# DCT_L3Interconnect register map
Vendor: Texas Instruments
Peripheral module from a debugger description file (folder omap4430).
Registers are 32-bit, access per field, reset 0x0 unless marked. A register's access mark holds for its fields unless they carry their own. Offsets are as the file gives them; lines under a group give offsets from that group; [hi:lo] are bit positions; {n}, {i} and the like mark numbered series; 'fields as' and 'values as' point back to an identical list; <NAME> marks a mode.

## DCT_L3Interconnect
0x00 DCT_VERSION ro reset not defined — IP Revision
  [31:0] REVISION
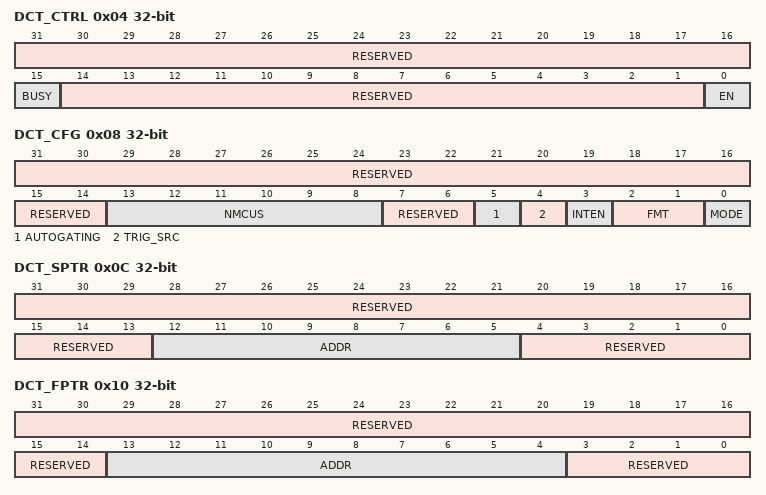
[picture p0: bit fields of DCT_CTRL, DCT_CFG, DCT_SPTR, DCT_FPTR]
0x04 DCT_CTRL — DCT control register
  [31:16] RESERVED ro — Read returns 0.
  [15] BUSY ro — IDCT/busy status 0: Idle 1: Busy
  [14:1] RESERVED ro — Read returns 0.
  [0] EN wo — Write 1 whenDCT_CFG[4] TRIG_SRC = 0 to start module operation. Read returns 0.
0x08 DCT_CFG — DCT configuration register
  [31:14] RESERVED ro — Read returns 0.
  [13:8] NMCUS rw — Number of MCUs (for FMT = 0, 1) or blocks (for FMT = 2) 0 = 1 MCU or block 1 = 2 MCUs or blocks ... 63 = 64 MCUs or blocks
  [7:6] RESERVED ro — Read returns 0.
  [5] AUTOGATING rw — Internal clock gating on interface and functional clocks 0: Clocks are free-running 1: Clocks are gated off in subblocks that are not required for operation.
  [4] TRIG_SRC rw — Trigger source 0: Memory mapper register 1: Hardware start signal
  [3] INTEN rw — 0: Interrupt disabled 1: Interrupt enabled
  [2:1] FMT rw — Data format 0: YUV4:2:0 format 1: YUV4:2:2 format 2: Sequential blocks format 3: Reserved
  [0] MODE rw — 0: DCT 1: IDCT
0x0C DCT_SPTR — Spatial-domain data pointer, byte address
  [31:13] RESERVED ro — Read returns 0.
  [12:5] ADDR rw — Address in 256-bit words Intention is that software write a byte address into the register. Hardware ignores the lowest 5 bits and bits 12..5 specifies the 256-bit/word memory address..
  [4:0] RESERVED ro — Read returns 0.
0x10 DCT_FPTR — Frequency-domain data pointer, byte address
  [31:14] RESERVED ro — Read returns 0.
  [13:4] ADDR rw — Address in 128-bit words. Intention is that software write a byte address into the register. Hardware ignores the lowest 4 bits and bits 13..4 specifies the 128-bit/word memory address.
  [3:0] RESERVED ro — Read returns 0.
